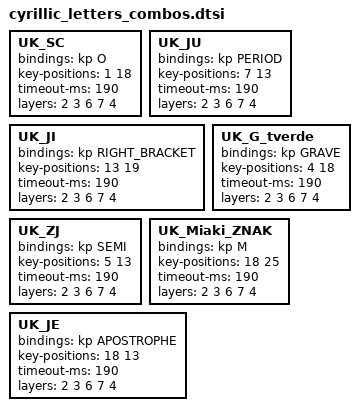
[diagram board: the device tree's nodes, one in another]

UK_SC {
	bindings = <&kp O>;
	key-positions = <1 18>;
	timeout-ms = <190>;
	layers = <2 3 6 7 4>;
};

UK_JU {
	bindings = <&kp PERIOD>;
	key-positions = <7 13>;
	timeout-ms = <190>;
	layers = <2 3 6 7 4>;
};

UK_JI {
	bindings = <&kp RIGHT_BRACKET>;
	key-positions = <13 19>;
	timeout-ms = <190>;
	layers = <2 3 6 7 4>;
};

UK_G_tverde {
	bindings = <&kp GRAVE>;
	key-positions = <4 18>;
	timeout-ms = <190>;
	layers = <2 3 6 7 4>;
};

UK_ZJ {
	bindings = <&kp SEMI>;
	key-positions = <5 13>;
	timeout-ms = <190>;
	layers = <2 3 6 7 4>;
};

UK_Miaki_ZNAK {
	bindings = <&kp M>;
	key-positions = <18 25>;
	timeout-ms = <190>;
	layers = <2 3 6 7 4>;
};

UK_JE {
	bindings = <&kp APOSTROPHE>;
	key-positions = <18 13>;
	timeout-ms = <190>;
	layers = <2 3 6 7 4>;
};
